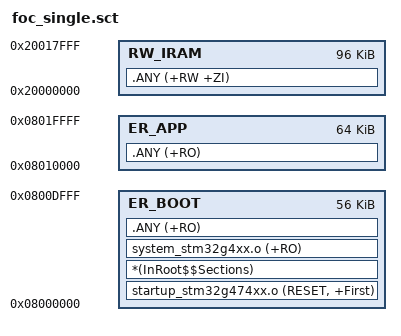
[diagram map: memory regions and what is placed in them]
; Bank1 尾部 0x0800E000..0x0800FFFF 留给双份配置，不放程序或常量。
LR_BOOT 0x08000000 0x0000E000 {
  ER_BOOT 0x08000000 0x0000E000 {
    startup_stm32g474xx.o (RESET, +First)
    *(InRoot$$Sections)
    system_stm32g4xx.o (+RO)
    .ANY (+RO)
  }
  RW_IRAM 0x20000000 0x00018000 {
    .ANY (+RW +ZI)
  }
}
LR_APP 0x08010000 0x00010000 {
  ER_APP 0x08010000 0x00010000 {
    .ANY (+RO)
  }
}
